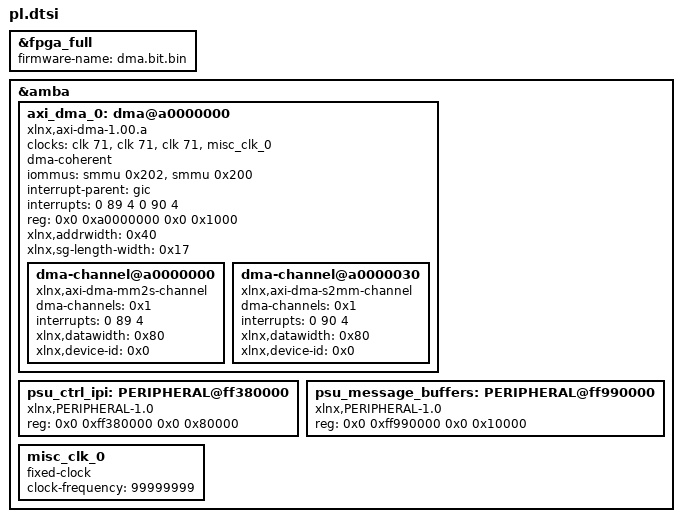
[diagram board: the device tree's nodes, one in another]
/*
 * CAUTION: This file is automatically generated by Xilinx.
 * Version:  
 * Today is: Mon Sep  3 11:03:19 2018
 */


/dts-v1/;
/plugin/;
/ {
	fragment@0 {
		target = <&fpga_full>;
		overlay0: __overlay__ {
			#address-cells = <2>;
			#size-cells = <2>;
			firmware-name = "dma.bit.bin";
		};
	};
	fragment@1 {
		target = <&amba>;
		overlay1: __overlay__ {
			axi_dma_0: dma@a0000000 {
				#dma-cells = <1>;
				clock-names = "s_axi_lite_aclk", "m_axi_sg_aclk", "m_axi_mm2s_aclk", "m_axi_s2mm_aclk";
				clocks = <&clk 71>, <&clk 71>, <&clk 71>, <&misc_clk_0>;
				//clocks = <&clk 71>, <&clk 71>, <&clk 71>, <&clk 71>;
				compatible = "xlnx,axi-dma-1.00.a";
				dma-coherent ;
			//	iommus  = <&smmu 0x200>, <&smmu 0x201>, <&smmu 0x202>;
				iommus  = <&smmu 0x202>, <&smmu 0x200>;
			//	iommus  = <&smmu 0x200>;
				interrupt-names = "mm2s_introut", "s2mm_introut";
				interrupt-parent = <&gic>;
				interrupts = <0 89 4 0 90 4>;
				reg = <0x0 0xa0000000 0x0 0x1000>;
				xlnx,addrwidth = <0x40>;
				xlnx,sg-length-width = <0x17>;
				dma-channel@a0000000 {
					compatible = "xlnx,axi-dma-mm2s-channel";
					dma-channels = <0x1>;
					interrupts = <0 89 4>;
					xlnx,datawidth = <0x80>;
					xlnx,device-id = <0x0>;
				};
				dma-channel@a0000030 {
					compatible = "xlnx,axi-dma-s2mm-channel";
					dma-channels = <0x1>;
					interrupts = <0 90 4>;
					xlnx,datawidth = <0x80>;
					xlnx,device-id = <0x0>;
				};
			};
			psu_ctrl_ipi: PERIPHERAL@ff380000 {
				compatible = "xlnx,PERIPHERAL-1.0";
				reg = <0x0 0xff380000 0x0 0x80000>;
			};
			psu_message_buffers: PERIPHERAL@ff990000 {
				compatible = "xlnx,PERIPHERAL-1.0";
				reg = <0x0 0xff990000 0x0 0x10000>;
			};
			misc_clk_0: misc_clk_0 {
				#clock-cells = <0>;
				clock-frequency = <99999999>;
				compatible = "fixed-clock";
			};
		};
	};
};
